# RA6M1 register map
Vendor: Renesas Electronics Corporation; Series: RA6; File version: 1.2
CPU: CM4 r0p1, little endian, MPU, FPU, VTOR, 4 interrupt priority bits
Registers are 8-bit, read-write, reset 0x0 unless marked. A register's access mark holds for its fields unless they carry their own. Offsets are from the block's base; [hi:lo] are bit positions; {n}, {i} and the like mark numbered series; 'fields as' and 'values as' point back to an identical list.

## GPT_ODC — PWM Delay Generation Circuit
Base 0x4007B000
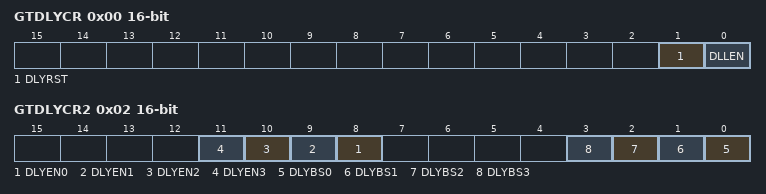
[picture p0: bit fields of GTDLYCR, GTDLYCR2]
0x00 GTDLYCR 16-bit — PWM Output Delay Control Register
  [1] DLYRST — PWM Delay Generation Circuit Reset
    0=Normal operation; 1=Reset
  [0] DLLEN — DLL Operation Enable
    0=Disable DLL operation; 1=Enable DLL operation
0x02 GTDLYCR2 16-bit — PWM Output Delay Control Register2
  [n+8] DLYEN{n} (n=0..3) — PWM Delay Generation Circuit enable for channel {n}
    0=Enable delay generation circuit of channel {n}; 1=Disable delay generation circuit of channel {n}
  [n] DLYBS{n} (n=0..3) — PWM Delay Generation Circuit bypass for channel {n}
    0=Bypass delay generation circuit of channel {n}; 1=Do not bypass delay generation circuit of channel {n}
{0x18+4i} GTDLYR{i}A (i=0..3) 16-bit (alternate view of GTDLYR{i}) — GTIOC{i}A Rising Output Delay Register
  [4:0] DLY — GTIOCnA Output Rising Edge Delay Setting
    0=No delay on rising edges; other=others (Delay of DLY/32 times the PCLKD period is applied.)
{0x1A+4i} GTDLYR{i}B (i=0..3) 16-bit (alternate view of GTDLYR{i}) — GTIOC{i}B Rising Output Delay Register
  [4:0] DLY — GTIOCnB Output Rising Edge Delay Setting
    values as GTDLYR0A.DLY
{0x28+4i} GTDLYF{i}A (i=0..3) 16-bit (alternate view of GTDLYF{i}) — GTIOC{i}A Falling Output Delay Register
  [4:0] DLY — GTIOCnA Output Falling Edge Delay Setting
    values as GTDLYR0A.DLY
{0x2A+4i} GTDLYF{i}B (i=0..3) 16-bit (alternate view of GTDLYF{i}) — GTIOC{i}B Falling Output Delay Register
  [4:0] DLY — GTIOCnB Output Falling Edge Delay Setting
    values as GTDLYR0A.DLY

## PORT0 — Port 0 Control Registers
Base 0x40040000
Same registers: PORT5 0x400400A0, PORT6 0x400400C0, PORT7 0x400400E0
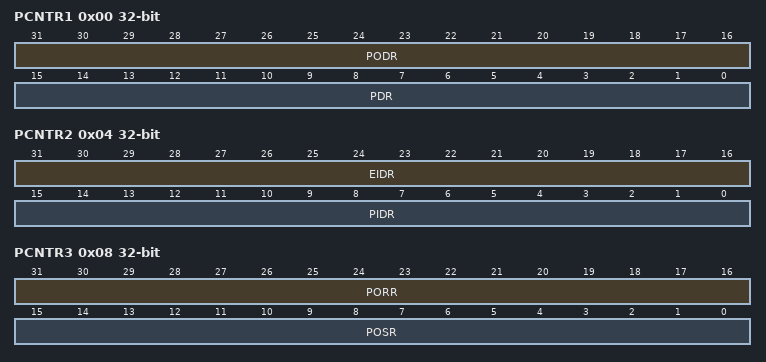
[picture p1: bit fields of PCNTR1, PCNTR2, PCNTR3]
0x00 PCNTR1 32-bit — Port Control Register 1
  [31:16] PODR — Pmn Output Data
    0=Low output; 1=High output
  [15:0] PDR — Pmn Direction
    0=Input (functions as an input pin); 1=Output (functions as an output pin)
0x00 PODR 16-bit (alternate view of PCNTR1) — Output data register
  [15:0] PODR — Pmn Output Data
    0=Low output; 1=High output
0x02 PDR 16-bit (alternate view of PCNTR1) — Data direction register
  [15:0] PDR — Pmn Direction
    values as PCNTR1.PDR
0x04 PCNTR2 32-bit ro (reset mask 0xFFFF0000) — Port Control Register 2
  [31:16] EIDR — Pmn Event Input Data
    0=Low input; 1=High input
  [15:0] PIDR — Pmn Input Data
    0=Low input; 1=High input
0x06 PIDR 16-bit ro reset not defined (alternate view of PCNTR2) — Input data register
  [15:0] PIDR — Pmn Input Data
    0=Low input; 1=High input
0x08 PCNTR3 32-bit wo — Port Control Register 3
  [31:16] PORR — Pmn Output Reset
    0=No affect to output; 1=Low output
  [15:0] POSR — Pmn Output Set
    0=No affect to output; 1=High output
0x08 PORR 16-bit wo (alternate view of PCNTR3) — Output reset register
  [15:0] PORR — Pmn Output Reset
    0=No affect to output; 1=Low output
0x0A POSR 16-bit wo (alternate view of PCNTR3) — Output set register
  [15:0] POSR — Pmn Output Set
    0=No affect to output; 1=High output

## PORT1 — Port 1 Control Registers
Base 0x40040020
Same registers: PORT2 0x40040040, PORT3 0x40040060, PORT4 0x40040080
Registers as PORT0; these are added or differ:
0x04 EIDR 16-bit ro reset not defined (alternate view of PCNTR2) — Event input data register
  [15:0] EIDR — Pmn Event Input Data
    0=Low input; 1=High input
0x08 PORR 16-bit wo (alternate view of PCNTR3) — Output set register
  [15:0] PORR — Pmn Output Reset
    0=No affect to output; 1=Low output
0x0A POSR 16-bit wo (alternate view of PCNTR3) — Output reset register
  [15:0] POSR — Pmn Output Set
    0=No affect to output; 1=High output
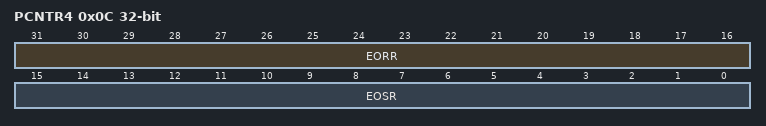
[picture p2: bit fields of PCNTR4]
0x0C PCNTR4 32-bit — Port Control Register 4
  [31:16] EORR — Pmn Event Output Reset
    0=No affect to output; 1=Low output
  [15:0] EOSR — Pmn Event Output Set
    0=No affect to output; 1=High output
0x0C EORR 16-bit (alternate view of PCNTR4) — Event output set register
  [15:0] EORR — Pmn Event Output Reset
    0=No affect to output; 1=Low output
0x0E EOSR 16-bit (alternate view of PCNTR4) — Event output reset register
  [15:0] EOSR — Pmn Event Output Set
    0=No affect to output; 1=High output
